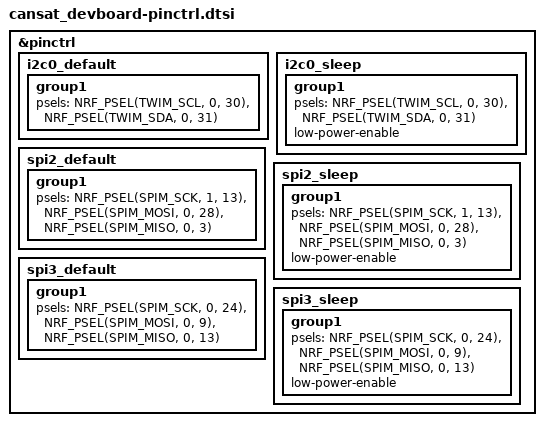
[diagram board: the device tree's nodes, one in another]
&pinctrl {
	//battery management I2C
	i2c0_default: i2c0_default {
		group1 {
			psels = <NRF_PSEL(TWIM_SCL, 0, 30)>,
				<NRF_PSEL(TWIM_SDA, 0, 31)>;
		};
	};

	i2c0_sleep: i2c0_sleep {
		group1 {
			psels = <NRF_PSEL(TWIM_SCL, 0, 30)>,
				<NRF_PSEL(TWIM_SDA, 0, 31)>;
			low-power-enable;
		};
	};

	//Lora SPI
	spi2_default: spi2_default {
		group1 {
			psels = <NRF_PSEL(SPIM_SCK, 1, 13)>,
				<NRF_PSEL(SPIM_MOSI, 0, 28)>,
				<NRF_PSEL(SPIM_MISO, 0, 3)>;
		};
	};

	spi2_sleep: spi2_sleep {
		group1 {
			psels = <NRF_PSEL(SPIM_SCK, 1, 13)>,
				<NRF_PSEL(SPIM_MOSI, 0, 28)>,
				<NRF_PSEL(SPIM_MISO, 0, 3)>;
			low-power-enable;
		};
	};

	//SD Card SPI
	spi3_default: spi3_default {
		group1 {
			psels = <NRF_PSEL(SPIM_SCK, 0, 24)>,
				<NRF_PSEL(SPIM_MOSI, 0, 9)>,
				<NRF_PSEL(SPIM_MISO, 0, 13)>;
		};
	};

	spi3_sleep: spi3_sleep {
		group1 {
			psels = <NRF_PSEL(SPIM_SCK, 0, 24)>,
				<NRF_PSEL(SPIM_MOSI, 0, 9)>,
				<NRF_PSEL(SPIM_MISO, 0, 13)>;
			low-power-enable;
		};
	};
};


